# nrf52 register map
Vendor: Nordic Semiconductor; Series: nrf52; File version: 1
CPU: CM4 r0p1, little endian, MPU, FPU, 3 interrupt priority bits
Registers are 32-bit, read-write, reset 0x0 unless marked. A register's access mark holds for its fields unless they carry their own. Offsets are from the block's base; [hi:lo] are bit positions; lines under a group give offsets from that group; 'fields as' and 'values as' point back to an identical list.

## SPIM0 — Serial Peripheral Interface Master with EasyDMA 0
Base 0x40003000
Same registers: SPIM1 0x40004000, SPIM2 0x40023000
0x10 TASKS_START wo — Start SPI transaction
  [0] TASKS_START
0x14 TASKS_STOP wo — Stop SPI transaction
  [0] TASKS_STOP
0x1C TASKS_SUSPEND wo — Suspend SPI transaction
  [0] TASKS_SUSPEND
0x20 TASKS_RESUME wo — Resume SPI transaction
  [0] TASKS_RESUME
0x104 EVENTS_STOPPED — SPI transaction has stopped
  [0] EVENTS_STOPPED
0x110 EVENTS_ENDRX — End of RXD buffer reached
  [0] EVENTS_ENDRX
0x118 EVENTS_END — End of RXD buffer and TXD buffer reached
  [0] EVENTS_END
0x120 EVENTS_ENDTX — End of TXD buffer reached
  [0] EVENTS_ENDTX
0x14C EVENTS_STARTED — Transaction started
  [0] EVENTS_STARTED
0x200 SHORTS — Shortcut register
  [17] END_START — Shortcut between END event and START task
    0=Disabled (Disable shortcut); 1=Enabled (Enable shortcut)
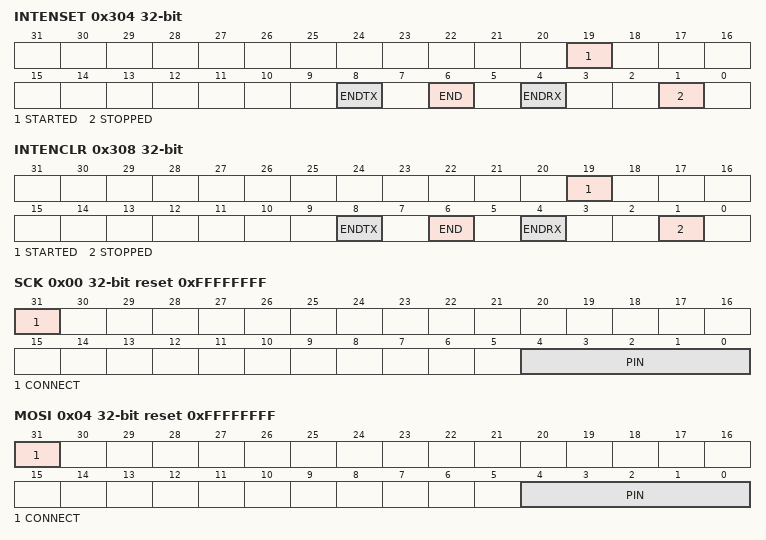
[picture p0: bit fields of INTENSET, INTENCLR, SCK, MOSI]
0x304 INTENSET — Enable interrupt
  [all] fields
    on read: 0=Disabled (Read: Disabled); 1=Enabled (Read: Enabled) | on write: 1=Set (Enable)
  [19] STARTED — Write '1' to Enable interrupt for STARTED event
  [8] ENDTX — Write '1' to Enable interrupt for ENDTX event
  [6] END — Write '1' to Enable interrupt for END event
  [4] ENDRX — Write '1' to Enable interrupt for ENDRX event
  [1] STOPPED — Write '1' to Enable interrupt for STOPPED event
0x308 INTENCLR — Disable interrupt
  [all] fields
    on read: 0=Disabled (Read: Disabled); 1=Enabled (Read: Enabled) | on write: 1=Clear (Disable)
  [19] STARTED — Write '1' to Disable interrupt for STARTED event
  [8] ENDTX — Write '1' to Disable interrupt for ENDTX event
  [6] END — Write '1' to Disable interrupt for END event
  [4] ENDRX — Write '1' to Disable interrupt for ENDRX event
  [1] STOPPED — Write '1' to Disable interrupt for STOPPED event
0x500 ENABLE — Enable SPIM
  [3:0] ENABLE — Enable or disable SPIM
    0=Disabled (Disable SPIM); 7=Enabled (Enable SPIM)
0x508 PSEL group — Unspecified
  0x00 SCK reset 0xFFFFFFFF — Pin select for SCK
    [31] CONNECT — Connection
      1=Disconnected; 0=Connected
    [4:0] PIN — Pin number
  0x04 MOSI reset 0xFFFFFFFF — Pin select for MOSI signal
    fields as PSEL.SCK
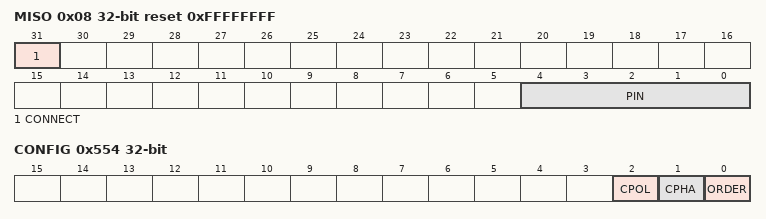
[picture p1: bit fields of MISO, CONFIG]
  0x08 MISO reset 0xFFFFFFFF — Pin select for MISO signal
    fields as PSEL.SCK
0x524 FREQUENCY reset 0x4000000 — SPI frequency. Accuracy depends on the HFCLK source selected.
  [31:0] FREQUENCY — SPI master data rate
    0x2000000=K125 (125 kbps); 0x4000000=K250 (250 kbps); 0x8000000=K500 (500 kbps); 0x10000000=M1 (1 Mbps); 0x20000000=M2 (2 Mbps); 0x40000000=M4 (4 Mbps); 0x80000000=M8 (8 Mbps)
0x534 RXD group — RXD EasyDMA channel
  0x00 PTR — Data pointer
  0x04 MAXCNT — Maximum number of bytes in receive buffer
    [7:0] MAXCNT
  0x08 AMOUNT ro — Number of bytes transferred in the last transaction
    [7:0] AMOUNT
  0x0C LIST — EasyDMA list type
    [2:0] LIST — List type
      0=Disabled (Disable EasyDMA list); 1=ArrayList (Use array list)
0x544 TXD group — TXD EasyDMA channel
  0x00 PTR — Data pointer
  0x04 MAXCNT — Maximum number of bytes in transmit buffer
    [7:0] MAXCNT
  0x08 AMOUNT ro — Number of bytes transferred in the last transaction
    [7:0] AMOUNT
  0x0C LIST — EasyDMA list type
    fields as RXD.LIST
0x554 CONFIG — Configuration register
  [2] CPOL — Serial clock (SCK) polarity
    0=ActiveHigh; 1=ActiveLow
  [1] CPHA — Serial clock (SCK) phase
    0=Leading (Sample on leading edge of clock, shift serial data on trailing edge); 1=Trailing (Sample on trailing edge of clock, shift serial data on leading edge)
  [0] ORDER — Bit order
    0=MsbFirst (Most significant bit shifted out first); 1=LsbFirst (Least significant bit shifted out first)
0x5C0 ORC — Over-read character. Character clocked out in case and over-read of the TXD buffer.
  [7:0] ORC

## Notices in the file
Copyright (c) 2010 - 2018, Nordic Semiconductor ASA
All rights reserved.
Redistribution and use in source and binary forms, with or without modification,
are permitted provided that the following conditions are met:
1. Redistributions of source code must retain the above copyright notice, this
list of conditions and the following disclaimer.
2. Redistributions in binary form, except as embedded into a Nordic
Semiconductor ASA integrated circuit in a product or a software update for
such product, must reproduce the above copyright notice, this list of
conditions and the following disclaimer in the documentation and/or other
materials provided with the distribution.
3. Neither the name of Nordic Semiconductor ASA nor the names of its
contributors may be used to endorse or promote products derived from this
software without specific prior written permission.
4. This software, with or without modification, must only be used with a
Nordic Semiconductor ASA integrated circuit.
5. Any software provided in binary form under this license must not be reverse
engineered, decompiled, modified and/or disassembled.
THIS SOFTWARE IS PROVIDED BY NORDIC SEMICONDUCTOR ASA "AS IS" AND ANY EXPRESS
OR IMPLIED WARRANTIES, INCLUDING, BUT NOT LIMITED TO, THE IMPLIED WARRANTIES
OF MERCHANTABILITY, NONINFRINGEMENT, AND FITNESS FOR A PARTICULAR PURPOSE ARE
DISCLAIMED. IN NO EVENT SHALL NORDIC SEMICONDUCTOR ASA OR CONTRIBUTORS BE
LIABLE FOR ANY DIRECT, INDIRECT, INCIDENTAL, SPECIAL, EXEMPLARY, OR
CONSEQUENTIAL DAMAGES (INCLUDING, BUT NOT LIMITED TO, PROCUREMENT OF SUBSTITUTE
GOODS OR SERVICES; LOSS OF USE, DATA, OR PROFITS; OR BUSINESS INTERRUPTION)
HOWEVER CAUSED AND ON ANY THEORY OF LIABILITY, WHETHER IN CONTRACT, STRICT
LIABILITY, OR TORT (INCLUDING NEGLIGENCE OR OTHERWISE) ARISING IN ANY WAY OUT
OF THE USE OF THIS SOFTWARE, EVEN IF ADVISED OF THE POSSIBILITY OF SUCH DAMAGE.
